# ATmega64M1 device description
Architecture: AVR8; Family: megaAVR
Programming and debug interfaces: ISP, HVPP, debugWIRE
Registers are 8-bit, access not given, no defined reset value unless marked. A register's access mark holds for its fields unless they carry their own. Offsets are from the block's base; lines under a group give offsets from that group; [hi:lo] are bit positions; {n}, {i} and the like mark numbered series; 'fields as' and 'values as' point back to an identical list; <NAME> marks a mode.

## Ordering variants
standard: 2.7 to 5.5 V

## Memory
prog space: start 0x0000 size 0x10000, little endian
  0x0000 FLASH size 0x10000 flash, rw, executable, page 0x100
  0xfc00 BOOT_SECTION_1 size 0x0400 flash, rw, executable, page 0x100
  0xf800 BOOT_SECTION_2 size 0x0800 flash, rw, executable, page 0x100
  0xf000 BOOT_SECTION_3 size 0x1000 flash, rw, executable, page 0x100
  0xe000 BOOT_SECTION_4 size 0x2000 flash, rw, executable, page 0x100
signatures space: start 0 size 3, little endian
  0 SIGNATURES size 3 signatures, ro
fuses space: start 0 size 0x0003, little endian
  0 FUSES size 0x0003 fuses, rw
lockbits space: start 0 size 0x0001, little endian
  0 LOCKBITS size 0x0001 lockbits, rw
data space: start 0x0000 size 0x1100, little endian
  0x0000 REGISTERS size 0x0020 regs
  0x0020 MAPPED_IO size 0x00e0 io
  0x0100 IRAM size 0x1000 ram
eeprom space: start 0x0000 size 0x0800, little endian
  0x0000 EEPROM size 0x0800 eeprom, rw, page 0x08
io space: start 0x00 size 0x40, little endian
osccal space: start 0 size 1, little endian
  0 OSCCAL size 1 osccal, ro

## Peripheral instances (address, pins/pin function, parameters)
PORTB at 0x00 — I/O Port
PORTC at 0x00 — I/O Port
PORTD at 0x00 — I/O Port
PORTE at 0x00 — I/O Port
CAN at 0x00 — Controller Area Network
AC at 0x00 — Analog Comparator
DAC at 0x00 — Digital-to-Analog Converter
CPU at 0x00 — CPU Registers
TC0 at 0x00 — Timer/Counter, 8-bit
TC1 at 0x00 — Timer/Counter, 16-bit
ADC at 0x00 — Analog-to-Digital Converter
LINUART at 0x00 — Local Interconnect Network
SPI at 0x00 — Serial Peripheral Interface
WDT at 0x00 — Watchdog Timer
EXINT at 0x00 — External Interrupts
EEPROM at 0x00
PSC at 0x00 — Power Stage Controller
FUSE at 0 in fuses — Fuses
LOCKBIT at 0 in lockbits — Lockbits

## Interrupts
0 RESET — External Pin, Power-on Reset, Brown-out Reset, Watchdog Reset and JTAG AVR Reset
1 ANACOMP0 — Analog Comparator 0
2 ANACOMP1 — Analog Comparator 1
3 ANACOMP2 — Analog Comparator 2
4 ANACOMP3 — Analog Comparator 3
5 PSC_FAULT
6 PSC_EC — PSC End of Cycle
7 INT0 — External Interrupt Request 0
8 INT1 — External Interrupt Request 1
9 INT2 — External Interrupt Request 2
10 INT3 — External Interrupt Request 3
11 TIMER1_CAPT — Timer/Counter1 Capture Event
12 TIMER1_COMPA — Timer/Counter1 Compare Match A
13 TIMER1_COMPB — Timer/Counter1 Compare Match B
14 TIMER1_OVF — Timer1/Counter1 Overflow
15 TIMER0_COMPA — Timer/Counter0 Compare Match A
16 TIMER0_COMPB — Timer/Counter0 Compare Match B
17 TIMER0_OVF — Timer/Counter0 Overflow
18 CAN_INT — CAN MOB, Burst, General Errors
19 CAN_TOVF — CAN Timer Overflow
20 LIN_TC — LIN Transfer Complete
21 LIN_ERR — LIN Error
22 PCINT0 — Pin Change Interrupt Request 0
23 PCINT1 — Pin Change Interrupt Request 1
24 PCINT2 — Pin Change Interrupt Request 2
25 PCINT3 — Pin Change Interrupt Request 3
26 SPI_STC — SPI Serial Transfer Complete
27 ADC — ADC Conversion Complete
28 WDT — Watchdog Time-Out Interrupt
29 EE_READY — EEPROM Ready
30 SPM_READY — Store Program Memory Read

## Properties
SIGNATURES: JTAGID=0x9684, SIGNATURE0=0x1e, SIGNATURE1=0x96, SIGNATURE2=0x84
OCD: OCD_REVISION=1, OCD_DATAREG=0x31, PROGBASE=0x0000

## LOCKBIT — Lockbits
Instances: LOCKBIT 0 in lockbits
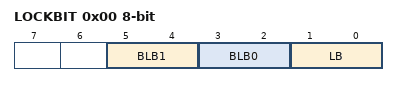
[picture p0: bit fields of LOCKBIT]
0x00 LOCKBIT
  [5:4] BLB1 — Boot Loader Protection Mode
    0=LPM_SPM_DISABLE (LPM and SPM prohibited in Boot Section); 1=LPM_DISABLE (LPM prohibited in Boot Section); 2=SPM_DISABLE (SPM prohibited in Boot Section); 3=NO_LOCK (No lock on SPM and LPM in Boot Section)
  [3:2] BLB0 — Boot Loader Protection Mode
    0=LPM_SPM_DISABLE (LPM and SPM prohibited in Application Section); 1=LPM_DISABLE (LPM prohibited in Application Section); 2=SPM_DISABLE (SPM prohibited in Application Section); 3=NO_LOCK (No lock on SPM and LPM in Application Section)
  [1:0] LB — Memory Lock
    0=PROG_VER_DISABLED (Further programming and verification disabled); 2=PROG_DISABLED (Further programming disabled); 3=NO_LOCK (No memory lock features enabled)
